# f28004x_nmi_intrupt_regs register map
Vendor: Texas Instruments
Peripheral module from a debugger description file (folder C2000).
Address unit: 16 bits
Registers are 16-bit, read-write, no defined reset value unless marked. A register's access mark holds for its fields unless they carry their own. Offsets are as the file gives them; lines under a group give offsets from that group; [hi:lo] are bit positions; {n}, {i} and the like mark numbered series; 'fields as' and 'values as' point back to an identical list; <NAME> marks a mode.

## NMI_INTRUPT_REGS — NMI INTRUPT Registers
0x00 NMICFG — NMI Configuration Register
  [0] NMIE — Global NMI Enable
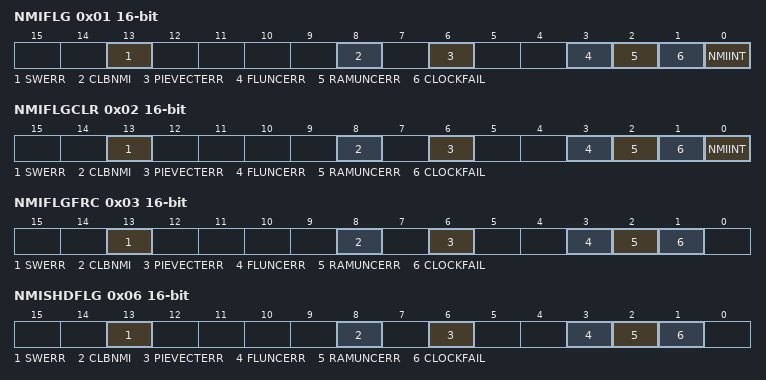
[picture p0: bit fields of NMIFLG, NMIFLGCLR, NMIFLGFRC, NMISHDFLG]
0x01 NMIFLG ro — NMI Flag Register (SYSRsn Clear)
  [13] SWERR — SW Error Force NMI Flag
  [8] CLBNMI — Configurable Logic Block NMI Flag
  [6] PIEVECTERR — PIE Vector Fetch Error Flag
  [3] FLUNCERR — Flash Uncorrectable Error NMI Flag
  [2] RAMUNCERR — RAM Uncorrectable Error NMI Flag
  [1] CLOCKFAIL — Clock Fail Interrupt Flag
  [0] NMIINT — NMI Interrupt Flag
0x02 NMIFLGCLR — NMI Flag Clear Register
  [13] SWERR — SWERR Flag Clear
  [8] CLBNMI — CLBNMI Flag Clear
  [6] PIEVECTERR — PIEVECTERR Flag Clear
  [3] FLUNCERR — FLUNCERR Flag Clear
  [2] RAMUNCERR — RAMUNCERR Flag Clear
  [1] CLOCKFAIL — CLOCKFAIL Flag Clear
  [0] NMIINT — NMIINT Flag Clear
0x03 NMIFLGFRC — NMI Flag Force Register
  [13] SWERR — SWERR Flag Force
  [8] CLBNMI — CLBNMI Flag Force
  [6] PIEVECTERR — PIEVECTERR Flag Force
  [3] FLUNCERR — FLUNCERR Flag Force
  [2] RAMUNCERR — RAMUNCERR Flag Force
  [1] CLOCKFAIL — CLOCKFAIL Flag Force
0x04 NMIWDCNT ro — NMI Watchdog Counter Register
  [15:0] NMIWDCNT — NMI Watchdog Counter
0x05 NMIWDPRD — NMI Watchdog Period Register
  [15:0] NMIWDPRD — NMI Watchdog Period
0x06 NMISHDFLG ro — NMI Shadow Flag Register
  [13] SWERR — SW Error Force NMI Flag
  [8] CLBNMI — Shadow CLBNMI flag
  [6] PIEVECTERR — Shadow PIEVECTERR Flag
  [3] FLUNCERR — Shadow FLUNCERR Flag
  [2] RAMUNCERR — Shadow RAMUNCERR Flag
  [1] CLOCKFAIL — Shadow CLOCKFAIL Flag
